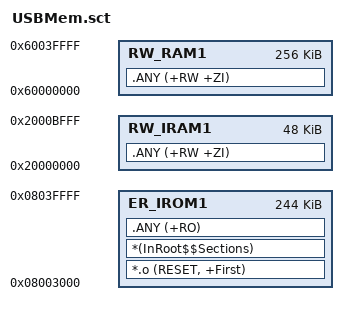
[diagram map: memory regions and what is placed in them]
; *************************************************************
; *** Scatter-Loading Description File generated by uVision ***
; *************************************************************

LR_IROM1 0x08003000 0x0003D000  {    ; load region size_region
  ER_IROM1 0x08003000 0x0003D000  {  ; load address = execution address
   *.o (RESET, +First)
   *(InRoot$$Sections)
   .ANY (+RO)
  }
  RW_RAM1 0x60000000 0x00040000  {  ; RW data
   .ANY (+RW +ZI)
  }
;  RW_RAM2 0x64000000 0x00080000  {
;   .ANY (+RW +ZI)
;   Memory.o(ZI_RAM2)
;  }
  RW_IRAM1 0x20000000 0x0000C000  {
   .ANY (+RW +ZI)
  }
}

